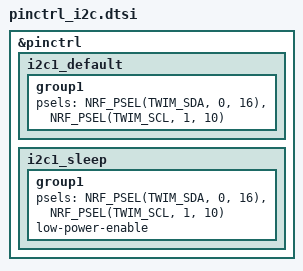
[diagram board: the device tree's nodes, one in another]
&pinctrl {
    i2c1_default: i2c1_default {
        group1 {
            psels = <NRF_PSEL(TWIM_SDA, 0, 16)>,
                    <NRF_PSEL(TWIM_SCL, 1, 10)>;
        };
    };

    i2c1_sleep: i2c1_sleep {
        group1 {
            psels = <NRF_PSEL(TWIM_SDA, 0, 16)>,
                    <NRF_PSEL(TWIM_SCL, 1, 10)>;
            low-power-enable;
        };
    };
};
